# lilium_network register map
Vendor: Nordic Semiconductor; Series: nrfXX; File version: 1
CPU: CM33 r0p4, little endian, MPU, no FPU, 3 interrupt priority bits, 30 interrupts
Registers are 32-bit, read-write, reset 0x0 unless marked. A register's access mark holds for its fields unless they carry their own. Offsets are from the block's base; [hi:lo] are bit positions; lines under a group give offsets from that group; {n}, {i} and the like mark numbered series; 'fields as' and 'values as' point back to an identical list.

## RADIO (part 3 of 3) — 2.4 GHz radio
Base 0x41008000
0x914 DECFILTERS group — Unspecified
  0x00 OUTMAIN group — Unspecified
    0x00 CKSEL reset 0x2 — Clock select register for the output outMain
      [2:0] CKSEL — Number of times to divide the base clock rate by 2. Exception: highest value gives BYPASS, ie. clock is disabled and data out is assigned directly from data in.
        0=ClkSel32M (CKSEL_32M); 1=ClkSel16M (CKSEL_16M); 2=ClkSel8M (CKSEL_8M); 3=ClkSel4M (CKSEL_4M); 4=ClkSel2M (CKSEL_2M); 5=ClkSel1M (CKSEL_1M); 6=ClkSel500K (CKSEL_500K); 7=ClkSelBypass (CKSEL_BYPASS)
  0x04 DECFIR0 group — Unspecified
    0x00 CKSEL reset 0x7 — Clock select register for the PUnit decFIR0 of type IP_FIR
      fields as DECFILTERS.OUTMAIN.CKSEL
    0x04 CONTROL reset 0x2 — Control register for the PUnit decFIR0 of type IP_FIR
      [1:0] TAPSEL — Tap-select: number of active taps minus 2
    0x08 COEFFS0 reset 0x4 — Coefficient register 0 for the PUnit decFIR0 of type IP_FIR
      [3:0] COEFF0 — Signed filter coefficient 0
    0x0C COEFFS1 reset 0x6 — Coefficient register 1 for the PUnit decFIR0 of type IP_FIR
      [3:0] COEFF1 — Signed filter coefficient 1
    0x10 COEFFS2 reset 0x6 — Coefficient register 2 for the PUnit decFIR0 of type IP_FIR
      [3:0] COEFF2 — Signed filter coefficient 2
    0x14 COEFFS3 — Coefficient register 3 for the PUnit decFIR0 of type IP_FIR
      [3:0] COEFF3 — Signed filter coefficient 3
  0x1C DECFIR1 group — Unspecified
    0x00 CKSEL — Clock select register for the PUnit decFIR1 of type IP_FIR
      fields as DECFILTERS.OUTMAIN.CKSEL
    0x04 CONTROL reset 0x4 — Control register for the PUnit decFIR1 of type IP_FIR
      [2:0] TAPSEL — Tap-select: number of active taps minus 2
    0x08 COEFFS0 reset 0x8 — Coefficient register 0 for the PUnit decFIR1 of type IP_FIR
      [5:0] COEFF0 — Signed filter coefficient 0
    0x0C COEFFS1 reset 0x10 — Coefficient register 1 for the PUnit decFIR1 of type IP_FIR
      [5:0] COEFF1 — Signed filter coefficient 1
    0x10 COEFFS2 reset 0x18 — Coefficient register 2 for the PUnit decFIR1 of type IP_FIR
      [5:0] COEFF2 — Signed filter coefficient 2
    0x14 COEFFS3 reset 0x10 — Coefficient register 3 for the PUnit decFIR1 of type IP_FIR
      [5:0] COEFF3 — Signed filter coefficient 3
    0x18 COEFFS4 — Coefficient register 4 for the PUnit decFIR1 of type IP_FIR
      [5:0] COEFF4 — Signed filter coefficient 4
    0x1C COEFFS5 — Coefficient register 5 for the PUnit decFIR1 of type IP_FIR
      [5:0] COEFF5 — Signed filter coefficient 5
  0x3C DECFIR2 group — Unspecified
    0x00 CKSEL reset 0x1 — Clock select register for the PUnit decFIR2 of type IP_FIR
      fields as DECFILTERS.OUTMAIN.CKSEL
    0x04 CONTROL reset 0x4 — Control register for the PUnit decFIR2 of type IP_FIR
      [2:0] TAPSEL — Tap-select: number of active taps minus 2
    0x08 COEFFS0 reset 0x8 — Coefficient register 0 for the PUnit decFIR2 of type IP_FIR
      [5:0] COEFF0 — Signed filter coefficient 0
    0x0C COEFFS1 reset 0x10 — Coefficient register 1 for the PUnit decFIR2 of type IP_FIR
      [5:0] COEFF1 — Signed filter coefficient 1
    0x10 COEFFS2 reset 0x18 — Coefficient register 2 for the PUnit decFIR2 of type IP_FIR
      [5:0] COEFF2 — Signed filter coefficient 2
    0x14 COEFFS3 reset 0x10 — Coefficient register 3 for the PUnit decFIR2 of type IP_FIR
      [5:0] COEFF3 — Signed filter coefficient 3
    0x18 COEFFS4 — Coefficient register 4 for the PUnit decFIR2 of type IP_FIR
      [5:0] COEFF4 — Signed filter coefficient 4
    0x1C COEFFS5 — Coefficient register 5 for the PUnit decFIR2 of type IP_FIR
      [5:0] COEFF5 — Signed filter coefficient 5
0x970 CHANNELFILTERS group — Unspecified
  0x00 OUTMAIN group — Unspecified
    0x00 CKSEL reset 0x2 — Clock select register for the output outMain
      fields as DECFILTERS.OUTMAIN.CKSEL
    0x04 SOURCE reset 0x4 — Source select register for the output outMain
      [3:0] SOURCE — Data source select
        15=SRC_INMAIN (NOT LEGAL); 0=SRC_IIR0 (NOT LEGAL); 1=SRC_IIR1 (NOT LEGAL); 2=SRC_NOTCHIIR0 (NOT LEGAL); 3=SrcNotchIIR1; 4=SrcDecFIR
  0x08 OUTPEAKDET group — Unspecified
    0x00 CKSEL reset 0x2 — Clock select register for the output outPeakDet
      fields as DECFILTERS.OUTMAIN.CKSEL
    0x04 SOURCE reset 0x3 — Source select register for the output outPeakDet
      fields as CHANNELFILTERS.OUTMAIN.SOURCE
  0x10 IIR0 group — Unspecified
    0x00 CKSEL reset 0x2 — Clock select register for the PUnit IIR0 of type IP_IIR2
      fields as DECFILTERS.OUTMAIN.CKSEL
    0x04 STATUS write-1-clears — Status register for the PUnit IIR0 of type IP_IIR2
      [1:0] IQSATURATION — Saturation status for I/Q (bit 0/1) component (bitwise write 1 to clear)
    0x08 COEFFSB0 reset 0x80 — Coefficient register B0 for the PUnit IIR0 of type IP_IIR2
      [11:0] COEFFB0 — Signed filter coefficient B0
    0x0C COEFFSB1 reset 0x80 — Coefficient register B1 for the PUnit IIR0 of type IP_IIR2
      [11:0] COEFFB1 — Signed filter coefficient B1
    0x10 COEFFSB2 — Coefficient register B2 for the PUnit IIR0 of type IP_IIR2
      [11:0] COEFFB2 — Signed filter coefficient B2
    0x14 COEFFSA1 reset 0xD00 — Coefficient register A1 for the PUnit IIR0 of type IP_IIR2
      [11:0] COEFFA1 — Signed filter coefficient A1
    0x18 COEFFSA2 — Coefficient register A2 for the PUnit IIR0 of type IP_IIR2
      [11:0] COEFFA2 — Signed filter coefficient A2
  0x2C IIR1 group — Unspecified
    0x00 CKSEL reset 0x2 — Clock select register for the PUnit IIR1 of type IP_IIR2
      fields as DECFILTERS.OUTMAIN.CKSEL
    0x04 STATUS write-1-clears — Status register for the PUnit IIR1 of type IP_IIR2
      fields as CHANNELFILTERS.IIR0.STATUS
    {0x8+4k} COEFFSB{k} reset 0x60 (k=0..2) — Coefficient register B{k} for the PUnit IIR1 of type IP_IIR2
      [11:0] COEFFB{k} — Signed filter coefficient B{k}
    0x14 COEFFSA1 reset 0xA00 — Coefficient register A1 for the PUnit IIR1 of type IP_IIR2
      [11:0] COEFFA1 — Signed filter coefficient A1
    0x18 COEFFSA2 reset 0x300 — Coefficient register A2 for the PUnit IIR1 of type IP_IIR2
      [11:0] COEFFA2 — Signed filter coefficient A2
  0x48 NOTCHIIR0 group — Unspecified
    0x00 CKSEL reset 0x2 — Clock select register for the PUnit notchIIR0 of type IP_IIR2
      fields as DECFILTERS.OUTMAIN.CKSEL
    0x04 SOURCE reset 0x1 — Source select register for the PUnit notchIIR0 of type IP_IIR2
      [3:0] SOURCE — Data source select
        15=SRC_INMAIN (NOT LEGAL); 0=SRC_IIR0 (NOT LEGAL); 1=SrcIIR1; 2=SRC_NOTCHIIR0 (NOT LEGAL); 3=SRC_NOTCHIIR1 (NOT LEGAL); 4=SrcDecFIR
    0x08 STATUS write-1-clears — Status register for the PUnit notchIIR0 of type IP_IIR2
      fields as CHANNELFILTERS.IIR0.STATUS
    0x0C COEFFSB0 reset 0x3C0 — Coefficient register B0 for the PUnit notchIIR0 of type IP_IIR2
      [11:0] COEFFB0 — Signed filter coefficient B0
    0x10 COEFFSB1 reset 0xAB0 — Coefficient register B1 for the PUnit notchIIR0 of type IP_IIR2
      [11:0] COEFFB1 — Signed filter coefficient B1
    0x14 COEFFSB2 reset 0x3C0 — Coefficient register B2 for the PUnit notchIIR0 of type IP_IIR2
      [11:0] COEFFB2 — Signed filter coefficient B2
    0x18 COEFFSA1 reset 0xAB0 — Coefficient register A1 for the PUnit notchIIR0 of type IP_IIR2
      [11:0] COEFFA1 — Signed filter coefficient A1
    0x1C COEFFSA2 reset 0x380 — Coefficient register A2 for the PUnit notchIIR0 of type IP_IIR2
      [11:0] COEFFA2 — Signed filter coefficient A2
  0x68 NOTCHIIR1 group — Unspecified
    0x00 CKSEL reset 0x7 — Clock select register for the PUnit notchIIR1 of type IP_IIR2
      fields as DECFILTERS.OUTMAIN.CKSEL
    0x04 STATUS write-1-clears — Status register for the PUnit notchIIR1 of type IP_IIR2
      fields as CHANNELFILTERS.IIR0.STATUS
    {0x8+4k} COEFFSB{k} (k=0..2) — Coefficient register B{k} for the PUnit notchIIR1 of type IP_IIR2
      [11:0] COEFFB{k} — Signed filter coefficient B{k}
    0x14 COEFFSA1 — Coefficient register A1 for the PUnit notchIIR1 of type IP_IIR2
      [11:0] COEFFA1 — Signed filter coefficient A1
    0x18 COEFFSA2 — Coefficient register A2 for the PUnit notchIIR1 of type IP_IIR2
      [11:0] COEFFA2 — Signed filter coefficient A2
  0x84 DECFIR group — Unspecified
    0x00 CKSEL reset 0x7 — Clock select register for the PUnit decFIR of type IP_FIR
      fields as DECFILTERS.OUTMAIN.CKSEL
    0x04 SOURCE reset 0x3 — Source select register for the PUnit decFIR of type IP_FIR
      [3:0] SOURCE — Data source select
        15=SRC_INMAIN (NOT LEGAL); 0=SRC_IIR0 (NOT LEGAL); 1=SrcIIR1; 2=SRC_NOTCHIIR0 (NOT LEGAL); 3=SrcNotchIIR1; 4=SRC_DECFIR (NOT LEGAL)
    0x08 CONTROL reset 0x4 — Control register for the PUnit decFIR of type IP_FIR
      [2:0] TAPSEL — Tap-select: number of active taps minus 2
    0x0C COEFFS0 reset 0x8 — Coefficient register 0 for the PUnit decFIR of type IP_FIR
      [5:0] COEFF0 — Signed filter coefficient 0
    0x10 COEFFS1 reset 0x10 — Coefficient register 1 for the PUnit decFIR of type IP_FIR
      [5:0] COEFF1 — Signed filter coefficient 1
    0x14 COEFFS2 reset 0x18 — Coefficient register 2 for the PUnit decFIR of type IP_FIR
      [5:0] COEFF2 — Signed filter coefficient 2
    0x18 COEFFS3 reset 0x10 — Coefficient register 3 for the PUnit decFIR of type IP_FIR
      [5:0] COEFF3 — Signed filter coefficient 3
    0x1C COEFFS4 — Coefficient register 4 for the PUnit decFIR of type IP_FIR
      [5:0] COEFF4 — Signed filter coefficient 4
    0x20 COEFFS5 — Coefficient register 5 for the PUnit decFIR of type IP_FIR
      [5:0] COEFF5 — Signed filter coefficient 5
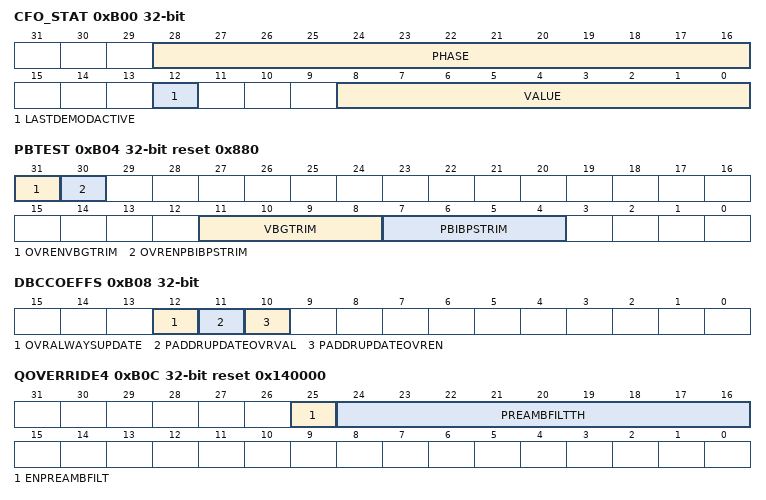
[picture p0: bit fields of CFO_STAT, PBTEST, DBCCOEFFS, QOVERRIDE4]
0xB00 CFO_STAT ro — Carrier freq. offset estimate
  [28:16] PHASE — Readout of last valid phase set in correlator (hypermode only) (signed)
  [12] LASTDEMODACTIVE — 0: Standard mode was used last 1: Hypermode was last used
  [8:0] VALUE — Readout of last valid decision level set in BitSlicer (signed)
0xB04 PBTEST reset 0x880 — Test: PB calibration
  [31] OVRENVBGTRIM — if '1' enable override for VBGTRIM
  [30] OVRENPBIBPSTRIM — if '1' enable override for PBIBPSTRIM
  [11:8] VBGTRIM — Trim code for VBG to FS_VCOREG
  [7:4] PBIBPSTRIM — Trim code for IBPS currents
0xB08 DBCCOEFFS — Test and Debug: DBC coefficients override
  [12] OVRALWAYSUPDATE — Zero means coefficients only updated when needed (default), set to 1 coefficients are always updated when the radio is enabled.
  [11] PADDRUPDATEOVRVAL
  [10] PADDRUPDATEOVREN
0xB0C QOVERRIDE4 reset 0x140000 — Trim value override register 4 for nRF52
  [25] ENPREAMBFILT — Enable preamble filter
  [24:16] PREAMBFILTTH — Threshold for the preamble filter
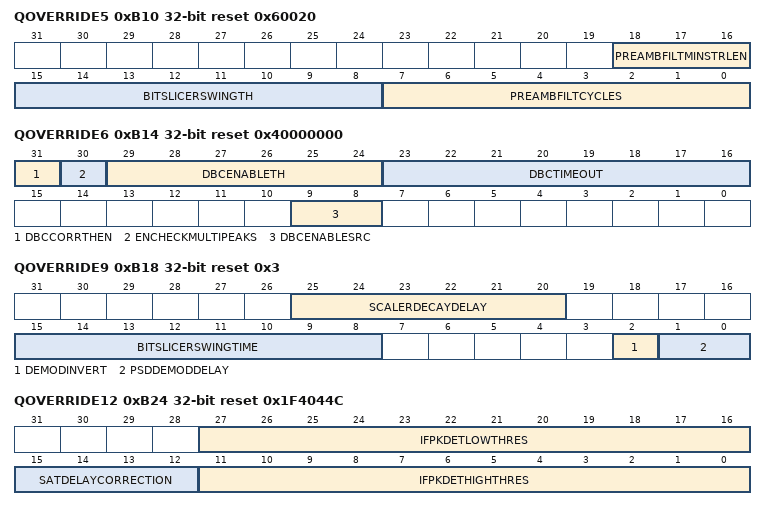
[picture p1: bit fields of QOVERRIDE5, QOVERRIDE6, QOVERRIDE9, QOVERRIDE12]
0xB10 QOVERRIDE5 reset 0x60020 — Trim value override register 5 for nRF52
  [18:16] PREAMBFILTMINSTRLEN — Override value for preambFiltMinStrLen
  [15:8] BITSLICERSWINGTH — Override value for bitSlicerSwingTh
  [7:0] PREAMBFILTCYCLES — Override value for preambFiltCycles
0xB14 QOVERRIDE6 reset 0x40000000 — Trim value override register 6 for nRF52
  [31] DBCCORRTHEN — Override value enable for DBCCORRTH and MFBSTRBOFFSET
  [30] ENCHECKMULTIPEAKS — Enable checking of several correlator peaks in hypermode
  [29:24] DBCENABLETH — Override value for correlator enable threshold
  [23:16] DBCTIMEOUT — Override value for correlator timeout,in bit periods (hypermode)
  [9:8] DBCENABLESRC — Override value for dbcEnableSrc
    0=Always on when not address match; 1=BBLogMag (When bbLogMag is above a threshold); 2=BitSlicerSwing (When a certain time has gone since the input to the bitslicer was above BITSLICERSWINGTH); 3=Both BBLogMag and BitSlicerSwing
0xB18 QOVERRIDE9 reset 0x3 — Trim value override register 9 for nRF52
  [25:20] SCALERDECAYDELAY — Decay delay for the IQ scaler
  [15:8] BITSLICERSWINGTIME
  [2] DEMODINVERT — Override value for demodInvert (standard and hyper)
  [1:0] PSDDEMODDELAY — Override value for psdDemodDelay (standard mode)
0xB24 QOVERRIDE12 reset 0x1F4044C — Trim value override register 12 for nRF52
  [27:16] IFPKDETLOWTHRES — Override value for IfpkDetLowThres
  [15:12] SATDELAYCORRECTION — Signed correction value for how much the saturation information is delayed from the input ADC samples to the samples being stored to RAM in direction finding operation
  [11:0] IFPKDETHIGHTHRES — Override value for IfpkDetHighThres
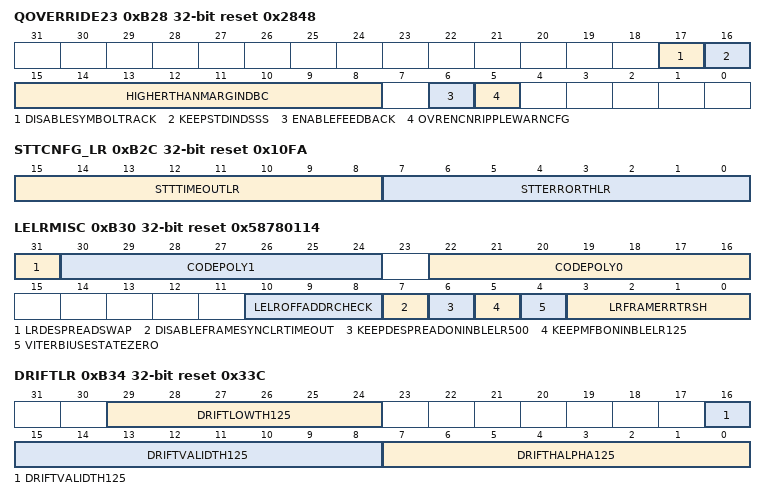
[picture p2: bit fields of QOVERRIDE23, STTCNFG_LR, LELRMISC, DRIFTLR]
0xB28 QOVERRIDE23 reset 0x2848 — Trim value override register 23 for nRF52
  [17] DISABLESYMBOLTRACK — Disable symbol tracking for IEEE 802.15.4 and BLE LR modes
  [16] KEEPSTDINDSSS — Keep standard demod in DSSS mode
  [15:8] HIGHERTHANMARGINDBC — Required peak height required for a double correlator peak to be considered higher than previous ones. The register value will be multiplied by 25 to obtain the actual margin. The bitfield is NOT subject to the enable override at bit position 31, and will always be enabled for hypermode.
  [6] ENABLEFEEDBACK — Enable decision feedback for matched filter bank
  [5] OVRENCNRIPPLEWARNCFG — Override enable for CNPEAKMINTHR and CNABSMAXTHR in the CNRIPPLEWARNCFG register
0xB2C STTCNFG_LR reset 0x10FA — Strobe time tracking configuration in long range mode
  [15:8] STTTIMEOUTLR — Strobe time tracking timeout in BLE LR mode
  [7:0] STTERRORTHLR — Strobe time tracking error threshold in BLE LR mode
0xB30 LELRMISC reset 0x58780114 — Miscellaneous Controls for Long Range
  [31] LRDESPREADSWAP — Swap de-spreader
  [30:24] CODEPOLY1 — Code Polynom 1
  [22:16] CODEPOLY0 — Code Polynom 0
  [10:8] LELROFFADDRCHECK — The number of chip periods earlier which it is allowed to declare frameSync in DecodeLELong
  [7] DISABLEFRAMESYNCLRTIMEOUT — Disable framesync timeout (early address match timeout) for BLE LR mode (hypermode).
  [6] KEEPDESPREADONINBLELR500 — Do not stop the clock to the Despreader in BLE LR 500 mode
  [5] KEEPMFBONINBLELR125 — Do not stop the clock to RxMFB in BLE LR 125 mode
  [4] VITERBIUSESTATEZERO — Use Viterbi state zero when flushing out bits for BLE LR
  [3:0] LRFRAMERRTRSH — Framer Receive Threshold
0xB34 DRIFTLR reset 0x33C — Drift Controls in Long Range
  [29:24] DRIFTLOWTH125 — Override value for driftLowTh, drift estimator (despreadLELLong)
  [16:8] DRIFTVALIDTH125 — Override value for driftValidTh, drift estimator (despreadLELLong)
  [7:0] DRIFTHALPHA125 — Override value for IIR feedback , drift estimator (despreadLELLong)
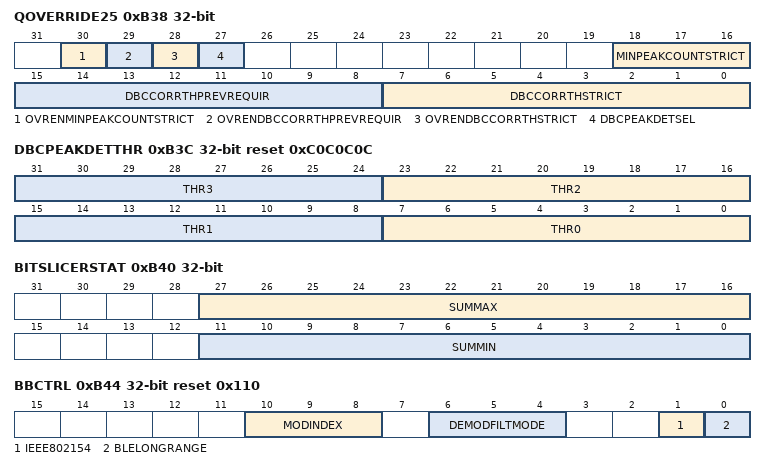
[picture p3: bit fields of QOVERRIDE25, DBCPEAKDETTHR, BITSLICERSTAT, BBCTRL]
0xB38 QOVERRIDE25 — TODO
  [30] OVRENMINPEAKCOUNTSTRICT — Override enable for MINPEAKCOUNTSTRICT
  [29] OVRENDBCCORRTHPREVREQUIR — Override enable for DBCCORRTHPREVREQUIR
  [28] OVRENDBCCORRTHSTRICT — Override enable for DBCCORRTHSTRICT
  [27] DBCPEAKDETSEL — DBC peak detector selection
    0=Classic (Use classic peak detector (backward compatible behavior)); 1=Differential (Use differential peak detector)
  [18:16] MINPEAKCOUNTSTRICT — Min number of peaks to detect before resyncing to another preamble while already working on a previous preamble in BleLrx.
  [15:8] DBCCORRTHPREVREQUIR — Correlation threshold for double correlator used in BleLr mode to reject a later resync using DBCCORRTHSTRICT.
  [7:0] DBCCORRTHSTRICT — Correlation threshold for double correlator used in BleLr mode to resync to another preamble while already working on a previous preamble.
0xB3C DBCPEAKDETTHR reset 0xC0C0C0C — Thresholds for each peak detector instance
  [8n+7:8n] THR{n} (n=0..3) — Diff threshold {n}
0xB40 BITSLICERSTAT ro — Payload status
  [27:16] SUMMAX — Number of received ones
  [11:0] SUMMIN — Number of received zeros
0xB44 BBCTRL reset 0x110 — Miscellaneous mode bits
  [10:8] MODINDEX — Modulation index for RxDBCCoeffGen and RxMFB
    0=0h25 (Modulation index h=0.25); 1=0h32 (Modulation index h=0.32); 2=0h5 (Modulation index h=0.5); 3=1h0 (Modulation index h=1.0); 4=2h0 (Modulation index h=2.0)
  [6:4] DEMODFILTMODE — Decimation mode in PantherDemodFilt
    0=2M (Decimation mode 2M); 1=1M (Decimation mode 1M); 3=250K (Decimation mode 250K)
  [1] IEEE802154 — Enable 15.4 mode (enabling both 15.4 and long range is not legal)
    0=Disable (IEEE802154_NO); 1=Enable (IEEE802154_YES)
  [0] BLELONGRANGE — Enable long range mode (enabling both 15.4 and long range is not legal)
    0=Disable (BLELONGRANGE_NO); 1=Enable (BLELONGRANGE_YES)
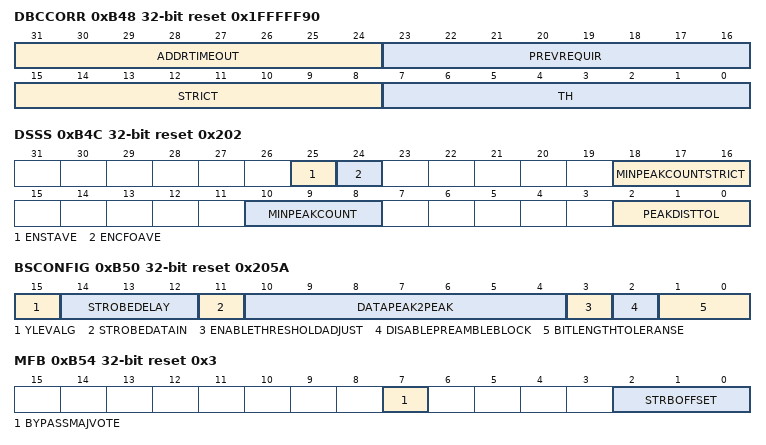
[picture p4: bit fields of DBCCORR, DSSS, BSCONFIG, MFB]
0xB48 DBCCORR reset 0x1FFFFF90 — Thresholds for the double correlator
  [31:24] ADDRTIMEOUT — Override value for address match timeout, [in bit periods] (hypermode). 0 means no timeout. If BALEN is 3, the actual value of DBCADDRTIMEOUT will be the value written to this register minus 8.
  [23:16] PREVREQUIR — Correlation threshold for double correlator used in BleLr mode to reject a later resync using DBCCORRTHSTRICT. Also applies for Ieee 802.15.4 mode
  [15:8] STRICT — Correlation threshold for double correlator used in BleLr mode to resync to another preamble while already working on a previous preamble. Also applies for Ieee 802.15.4 mode
  [7:0] TH — Correlation threshold for double correlator in normal operation
0xB4C DSSS reset 0x202 — DSSS synchronizer trim values
  [25] ENSTAVE — Enable strobe time averaging
  [24] ENCFOAVE — Enable CFO averaging
  [18:16] MINPEAKCOUNTSTRICT — Min number of peaks to detect before resyncing to another preamble while already working on a previous preamble in BleLrx. Also applies for Ieee 802.15.4 mode
  [10:8] MINPEAKCOUNT — Override for dsssMinPeakCount
  [2:0] PEAKDISTTOL — Override for dsssPeakDistanceTolerance
0xB50 BSCONFIG reset 0x205A — Bitslicer configuration
  [15] YLEVALG — Override for bsYlevAlg
  [14:12] STROBEDELAY — Override for bsStrobeDelay
  [11] STROBEDATAIN — Override for bsStrobeDataIn
  [10:4] DATAPEAK2PEAK — Override for bsDataPeak2Peak
  [3] ENABLETHRESHOLDADJUST — Override for bsEnableThresholdAdjust
  [2] DISABLEPREAMBLEBLOCK — Override for bsDisablePreambleBlock
  [1:0] BITLENGTHTOLERANSE — Override for bsBitLengthToleranse
0xB54 MFB reset 0x3 — Matched Filter Bank (MFB) configuration
  [7] BYPASSMAJVOTE — Bypass majority vote
    0=PASS (Majority vite); 1=BYPASS (Bypass through majority vote)
  [2:0] STRBOFFSET — Override value for strobe offset
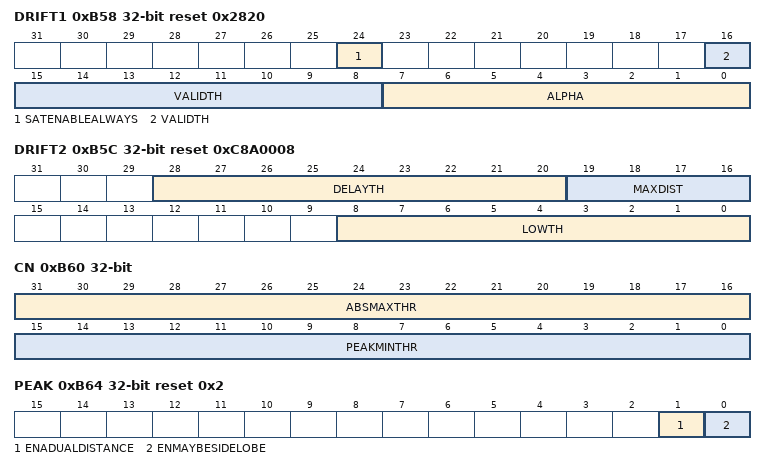
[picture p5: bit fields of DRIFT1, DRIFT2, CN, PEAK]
0xB58 DRIFT1 reset 0x2820 — Drift Estimator configuration
  [24] SATENABLEALWAYS — Enable saturation in drift calculator for all modes
  [16:8] VALIDTH — Override value for driftValidTh, drift estimator (hypermode)
  [7:0] ALPHA — Override value for IIR feedback , drift estimator (hypermode)
0xB5C DRIFT2 reset 0xC8A0008 — Drift Estimator configuration
  [28:20] DELAYTH — Override value for driftDelayTh, drift estimator (hypermode)
  [19:16] MAXDIST — Override value for driftMaxDist, drift estimator (hypermode)
  [8:0] LOWTH — Override value for driftLowTh, drift estimator (hypermode)
0xB60 CN — Configuration for the CNRIPPLEWARN functionality used for BLE LR. Configuration is only enabled when OVRENCNRIPPLEWARNCFG in OVERRIDE23 is set
  [31:16] ABSMAXTHR — maximum baseline value before the peak at the double correlator output. if the baseline value is above the threshold, the following peak will be ignored. this value is ignored when CNABSMAXTHR is set to 0x0000.
  [15:0] PEAKMINTHR — Required peak height compared to baseline level measured just before the peak at the double correlator output. If the peak height is below the threshold, it will be ignored. This feature is disabled when CNPEAKMINTHR is set to 0x0000.
0xB64 PEAK reset 0x2 — Peak detector configuration
  [1] ENADUALDISTANCE — Allow dual distance between peaks
  [0] ENMAYBESIDELOBE — Ignore peaks from DBC which look like sidelobes
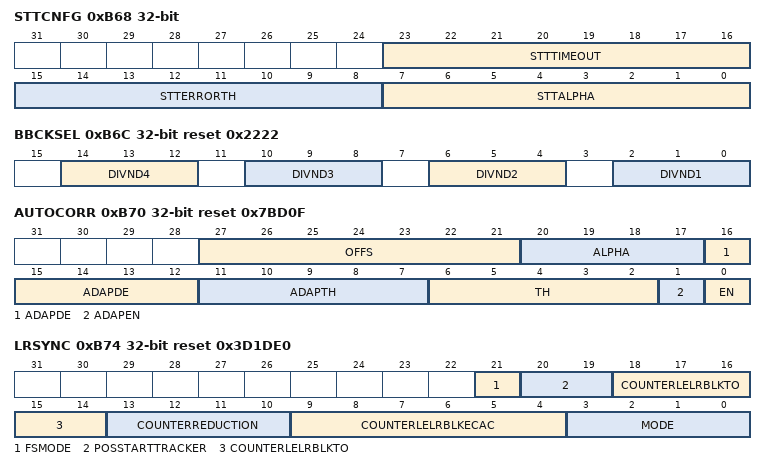
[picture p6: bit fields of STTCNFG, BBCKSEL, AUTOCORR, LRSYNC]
0xB68 STTCNFG — Strobe time tracking Configuration (Symbol Timing)
  [23:16] STTTIMEOUT — Strobe time tracking: adjustment timeout (min distance in symbolperiods between strobe adjustments in same direction)
  [15:8] STTERRORTH — Strobe time tracking: strobe time error threshold
  [7:0] STTALPHA — Strobe time tracking: IIR filter alpha
0xB6C BBCKSEL reset 0x2222 — Clock rates
  [all] fields
    0=32M (Select clock rate 32M); 1=16M (Select clock rate 16M); 2=8M (Select clock rate 8M); 3=4M (Select clock rate 4M); 4=2M (Select clock rate 2M); 5=1M (Select clock rate 1M); 6=500K (Select clock rate 500K); 7=Disabled (Select clock OFF)
  [14:12] DIVND4 — Hyper demod clock rate 2
  [10:8] DIVND3 — Hyper demod clock rate 1
  [6:4] DIVND2 — Standard demod clock rate 2
  [2:0] DIVND1 — Standard demod clock rate 1
0xB70 AUTOCORR reset 0x7BD0F — Autocorrelator configuration
  [27:21] OFFS — Offset for comparing between current and historical AC magnitude
  [20:17] ALPHA — Gain factor for low pass filter used to smoothen autocorrelator output. Set to 0000 indicates to select Max filter instead of LPF.
  [16:12] ADAPDE — A ratio to decay the autocorrelator ratio threshold when using adaptive threshold and a weak peak is found.
  [11:7] ADAPTH — A ratio to update the autocorrelator ratio threshold when adaptive threshold is enabled and a strong peak is found. Fraction of highest correlator match historically seen. Setting of 0.8125 is default.
  [6:2] TH — Default correlator threshold for deciding if valid correlator match is seen. Low setting of 0.10 is default.
  [1] ADAPEN — Enable adaptive autocorrelator threshold settings based on historically observed correlator output values.
  [0] EN — Enable autocorrelator gating of peaks.
0xB74 LRSYNC reset 0x3D1DE0 — LrSyncEngine configuration
  [21] FSMODE — Select between classic and MLSD based frame sync
    0=classic mode; 1=MLSD mode
  [20:19] POSSTARTTRACKER — A toggle to tell when to start the trackers inside each LelrBlk125.
    0=disabled for all times; 1=enabled after FEC1 is decoded; 2=enabled after frame sync is achieved; 3=enabled after LelrBlk125 is activated
  [18:14] COUNTERLELRBLKTO — A counter is used to reset the LelrBlk125 block that is active. It counts the number of outputs from DeSpreadLELong and compares it with this configured value to see whether a timeout event happens. The range is 32 to 60. Default value is 52.
  [13:10] COUNTERREDUCTION — When a strong peak event is triggered and the average peak strength is higher than the history stored in the block, the timeout counter is reduced by the number configured in this register. The default value is 7.
  [9:4] COUNTERLELRBLKECAC — A counter is used to indicate the time window of e-CAC check. It counts the number of outputs from DeSpreadLELong and compares it with this configured value to see whether e-CAC result is valid.
  [3:0] MODE — Modifying how the multiple lr125Front modules are used when synchronizing.
    0=AllFrontends (Use all the front ends); 1=OneFrontend (Use only one front end)
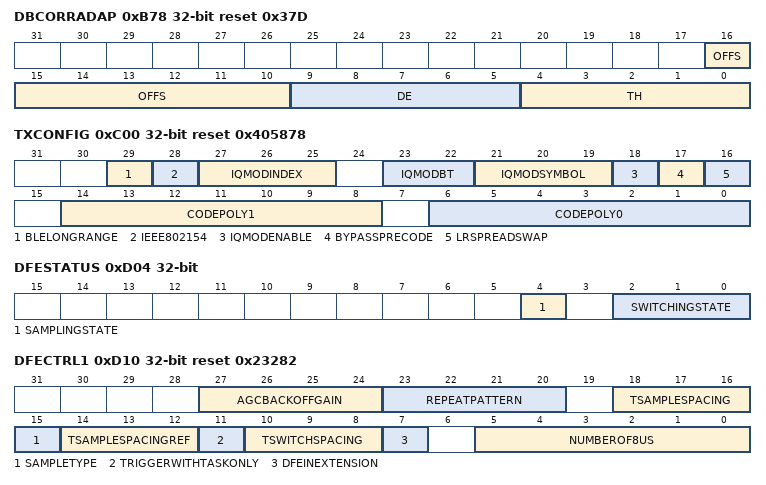
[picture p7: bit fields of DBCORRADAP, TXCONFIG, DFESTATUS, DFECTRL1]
0xB78 DBCORRADAP reset 0x37D — Adaptive thresholds for double correlator.
  [16:10] OFFS — Offset for comparing between current and historical DBC magnitude
  [9:5] DE — A ratio to decay the DBC ration threshold when using adaptive threshold and a weak peak is found.
  [4:0] TH — A ratio to update the DBC ratio threshold when adaptive threshold is enabled and a strong peak is found. Fraction of highest correlator match historically seen. Setting of 0.90625 is default.
0xB7C QOVERRIDE26 reset 0x1 — Override for selecting whether to use LrSyncEngine or the classic demodulator.
  [0] USELRSYNCENGINE — Select whether to use LrSyncEngine or the classic demodulator.
    0=Classic (use classic demodulator); 1=LrSyncEngine (Use LrSyncEngine demodulator)
0xC00 TXCONFIG reset 0x405878 — Tx configuration
  [29] BLELONGRANGE — Enable Tx for BLE long range modes (Do not enable both Ieee802154_250Kbit and BLE long range)
    0=Disabled (Disable Tx for BLE long range modes); 1=Enabled (Enable Tx for BLE long range modes)
  [28] IEEE802154 — Enable Tx for Ieee802154_250Kbit mode and long range modes (Do not enable both Ieee802154_250Kbit and long range)
    0=Disabled (Disable Tx for Ieee802154_250Kbit mode); 1=Enabled (Enable Tx for Ieee802154_250Kbit mode)
  [27:25] IQMODINDEX — IQMOD modulation index
    0=ModIndex0h25 (Modulation index = 0.25(Future)); 1=ModIndex0h32 (Modulation index = 0.32(Future)); 2=ModIndex0h5 (Modulation index = 0.5(Future)); 3=ModIndex1h0 (Modulation index = 1(Future)); 4=ModIndex2h0 (Modulation index = 2(Future))
  [23:22] IQMODBT — IQMOD GFSK bandwidth
    0=0BT55 (BT=0.55); 1=0BT60 (BT=0.60)
  [21:19] IQMODSYMBOL — IQMOD additional symbol mapping not set by MODE(Future)
  [18] IQMODENABLE — Enable IQ modulator
  [17] BYPASSPRECODE — Bypass MSK precoding
  [16] LRSPREADSWAP — Swap pattern mapping. Default 0, 0 is mapped to a 0011 sequence, 1 is mapped to a 1100 sequence. If swap bit is set, 1 is mapped to a 0011 sequence, 0 is mapped to a 1100 sequence.
  [14:8] CODEPOLY1 — Code polynomial 1
  [6:0] CODEPOLY0 — Code polynomial 0
0xD00 DFEMODE — Whether to use Angle-of-Arrival (AOA) or Angle-of-Departure (AOD)
  [1:0] DFEOPMODE — Direction finding operation mode
    0=Disabled (Direction finding mode disabled); 2=AoD (Direction finding mode set to AoD); 3=AoA (Direction finding mode set to AoA)
0xD04 DFESTATUS ro — DFE status information
  [4] SAMPLINGSTATE — Internal state of sampling state machine
    0=Idle (Sampling state Idle); 1=Sampling state Sampling
  [2:0] SWITCHINGSTATE — Internal state of switching state machine
    0=Idle (Switching state Idle); 1=Offset (Switching state Offset); 2=Guard (Switching state Guard); 3=Ref (Switching state Ref); 4=Switching state Switching; 5=Ending (Switching state Ending)
0xD10 DFECTRL1 reset 0x23282 — Various configuration for Direction finding
  [27:24] AGCBACKOFFGAIN — Gain will be lowered by the specified number of gain steps at the start of CTE
  [23:20] REPEATPATTERN — Repeat every antenna pattern N times.
    0=NoRepeat (Do not repeat (1 time in total))
  [18:16] TSAMPLESPACING — Interval between samples in the SWITCHING period when CTEINLINECTRLEN is 0
    1=4us; 2=2us; 3=1us; 4=500ns (0.5us); 5=250ns (0.25us); 6=125ns (0.125us)
  [15] SAMPLETYPE — Whether to sample I/Q or magnitude/phase
    0=IQ (Complex samples in I and Q); 1=MagPhase (Complex samples as magnitude and phase)
  [14:12] TSAMPLESPACINGREF — Interval between samples in the REFERENCE period
    0=8us; 1=4us; 2=2us; 3=1us; 4=500ns (0.5us); 5=250ns (0.25us); 6=125ns (0.125us)
  [11] TRIGGERWITHTASKONLY — Trigger AoA/AoD procedure using only task
    1=OnlyTask (Only allow triggering a procedure with TASKS_DFESTART); 0=Multiple (Trigger also with other signals)
  [10:8] TSWITCHSPACING — Interval between every time the antenna is changed in the SWITCHING state
    0=8us; 1=4us; 2=2us; 3=1us; 4=500ns (0.5us); 5=250ns (0.25us)
  [7] DFEINEXTENSION — Add CTE extension and do antenna switching/sampling in this extension
    1=CRC (AoA/AoD procedure triggered at end of CRC); 0=Payload (Antenna switching/sampling is done in the packet payload)
  [5:0] NUMBEROF8US — Length of the AoA/AoD procedure in number of 8 us units
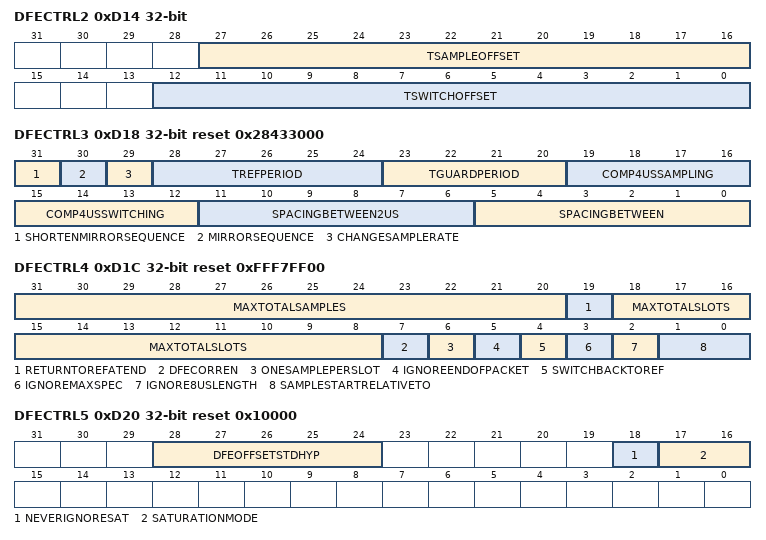
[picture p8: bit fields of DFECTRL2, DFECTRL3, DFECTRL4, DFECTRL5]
0xD14 DFECTRL2 — Start offset for Direction finding
  [27:16] TSAMPLEOFFSET — Signed value offset before starting sampling in number of 16M cycles relative to the beginning of the REFERENCE state - 12 us after switching start
  [12:0] TSWITCHOFFSET — Signed value offset after the end of the CRC before starting switching in number of 16M cycles
0xD18 DFECTRL3 reset 0x28433000 — Various hacker/tuning configuration for Direction finding
  [31] SHORTENMIRRORSEQUENCE — Applies only when MIRRORSEQUENCE is set. Selects whether to repeat the end pattern (in both ends) or not
    0=Disable (End patterns are repeated); 1=Enable (End patterns are not repeated)
  [30] MIRRORSEQUENCE — When reaching the last antenna pattern, it repeats that pattern, and then goes back down again.
    0=Disable (Do not mirror the sequence); 1=Enable (Mirror the sequence)
  [29] CHANGESAMPLERATE — Whether to have the ability to have separate sampling rate in the REFERENCE period vs the SWITCHING state
    0=Same (Always use sample spacing given by TSAMPLESPACINGREF); 1=Change (Use TSAMPLESPACINGREF in the REFERENCE period, and TSAMPLESPACING or CTEINLINEAODRXMODExUS in the SWITCHING period)
  [28:24] TREFPERIOD — Length of REFERENCE period in number of microseconds, normally 8
  [23:20] TGUARDPERIOD — Length of GUARD period in number of microseconds, normally 4
  [19:16] COMP4USSAMPLING — Number of 4us periods to subtract from numberOf8us when calculating total number of samples to capture
  [15:12] COMP4USSWITCHING — Number of 4us periods to subtract from numberOf8us when calculating total number of antenna slots switches
  [11:6] SPACINGBETWEEN2US — Same as SPACINGBETWEEN when using CTEINLINECTRL and CTEType is 2 us slots
  [5:0] SPACINGBETWEEN — Signed tuning value for the spacing between the last sample in the reference period and the first sample in the first sample slot
0xD1C DFECTRL4 reset 0xFFF7FF00 — Various hacker/tuning configuration for Direction finding
  [31:20] MAXTOTALSAMPLES — Maximum number of samples to capture
  [19] RETURNTOREFATEND — Start position of repeated part of switching pattern sequence
    0=Disable (Return to SWITCHPATTERN[2] after reaching the end of the switching pattern sequence); 1=Enable (Return to SWITCHPATTERN[1] after reaching the end of the switching pattern sequence)
  [18:8] MAXTOTALSLOTS — Maximum number of antenna slots
  [7] DFECORREN — Enable correlator before Direction Finding samples
    0=Disable correlator; 1=Enable correlator
  [6] ONESAMPLEPERSLOT — TSAMPLESPACING is ignored for the samples taken in the SWITCHING state TSAMPLESPACINGREF is still used for the first samples (REFERENCE period)
  [5] IGNOREENDOFPACKET — Ignore that the UTxRxChain says that the packet has been received Continue running if more time to run
    0=Do not ignore the end of packet; 1=Ignore the end of packet
  [4] SWITCHBACKTOREF — Insert reference antenna(SWITCHPATTERN[1]) between antenna switches, from SWITCHPATTERN[2] onwards
    0=Disable (Do not insert reference antenna between switches); 1=Enable (Insert reference antenna between switches)
  [3] IGNOREMAXSPEC — Ignore the maximum number of samples and antenna slots specified with MAXTOTALSAMPLES and MAXTOTALSLOTS
    0=DoNotIgnore (Use the max specs); 1=Ignore the max specs
  [2] IGNORE8USLENGTH — Ignore the length specification in numberOf8us
    0=DoNotIgnore (Use the length specification); 1=Ignore the length specification
  [1:0] SAMPLESTARTRELATIVETO — Start point of TSAMPLEOFFSET sampling relative to which part in the switching state machine
    0=Reference (At the start of the reference antenna period); 1=Switching (At the start of antenna switching after the reference antenna period); 2=Trigger (When it is triggered Either TASKS_DFESTART, address match or AoA/AoD procedure trigger source); 3=Guard (At the start of the GUARD period)
0xD20 DFECTRL5 reset 0x10000 — Various hacker/tuning configuration for Direction finding
  [28:24] DFEOFFSETSTDHYP — Tuning of the timing difference between the hypermode demodulator and the standard demodulator for the DFE start event, in 62.5 ns units
  [18] NEVERIGNORESAT — Selects whether saturation (being reported from the radio front-end) should be ignored in the beginning of the slot or not
    0=IGNORE (Saturation being indicated from the front-end is ignored if it happens in the first 40 percent of the sample spacing after a sample was saved to RAM); 1=NEVERIGNORE (Saturation is always reported in RAM if detected by the frontend)
  [17:16] SATURATIONMODE — Set how input saturation will be present in the captured samples
    0=OFF (No saturation is presented); 1=SETMINVAL (Saturation is marked by setting both I and Q to -32768 (or mag/phase if SAMPLETYPE is 1)); 2=SATURATIONBIT (Bit 15 of both the I and Q values indicates saturation. I and Q are hence only 15 bit values)
0xD28 SWITCHPATTERN — GPIO patterns to be used for each antenna
  [7:0] SWITCHPATTERN — Fill array of GPIO patterns for antenna control
0xD2C CLEARPATTERN wo — Clear the GPIO pattern array for antenna control
  [0] CLEARPATTERN — Clear the GPIO pattern array for antenna control Behaves as a task register, but does not have PPI nor IRQ
0xD30 PSEL group — Unspecified
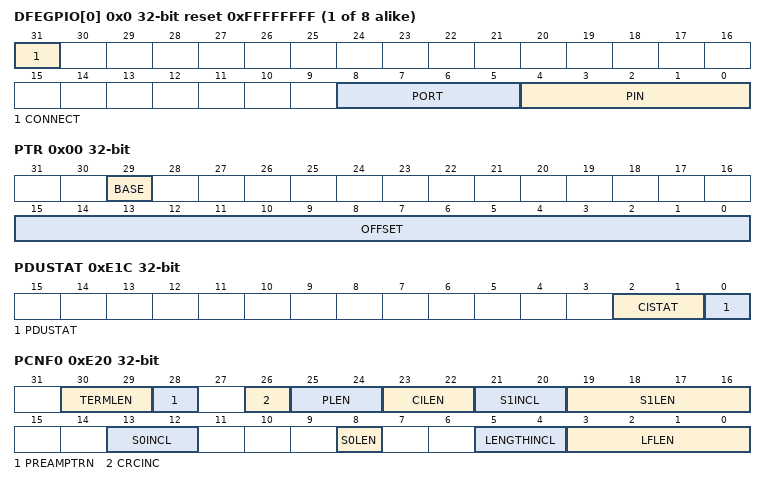
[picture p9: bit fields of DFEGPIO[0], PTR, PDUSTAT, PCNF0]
  {0x0+4j} DFEGPIO[{j}] (j=0..7) reset 0xFFFFFFFF — Description collection: Pin select for DFE pin n
    [31] CONNECT — Connection
      1=Disconnected; 0=Connected
    [8:5] PORT — Port number
    [4:0] PIN — Pin number
0xD50 DFEPACKET group — DFE packet EasyDMA channel
  0x00 PTR — Data pointer
    [29] BASE
    [15:0] OFFSET — Data pointer
  0x04 MAXCNT reset 0x1000 — Maximum number of buffer words to transfer
    [13:0] MAXCNT
  0x08 AMOUNT ro — Number of samples transferred in the last transaction
    [13:0] AMOUNT
  0x0C ENABLE — Unspecified
    [0] ENABLE
      1=Disabled; 0=Enabled
0xD64 DFEDMASTART — Manually start DmaChannelPeripheral for DFE
  [0] DFEDMASTART
0xD68 DFEDMASTOP — Force stop DmaChannelPeripheral for DFE
  [0] DFEDMASTOP
0xE00 CNTPSTART wo — Start packet counter
  [0] TRIG
0xE04 CNTPSTOP wo — Stop packet counter
  [0] TRIG
0xE08 CNTPCLEAR wo — Clear packet counter
  [0] TRIG
0xE0C CRCSTATUS ro
  [0] CRCSTATUS — CRC status of packet received
    0=CRCError (Packet received with CRC error); 1=CRCOk (Packet received with CRC ok)
0xE10 RXMATCH ro — Received address
  [2:0] RXMATCH
0xE14 RXCRC ro — CRC field of previously received packet
  [23:0] RXCRC
0xE18 DAI ro — Device address match index
  [2:0] DAI
0xE1C PDUSTAT ro — Payload status
  [2:1] CISTAT — Status on what rate packet is received with in Long Range
    0=LR125kbit (Frame is received at 125 kbps); 1=LR500kbit (Frame is received at 500 kbps)
  [0] PDUSTAT — Status on payload length vs. PCNF1.MAXLEN
    0=LessThan (Payload less than PCNF1.MAXLEN); 1=GreaterThan (Payload greater than PCNF1.MAXLEN)
0xE20 PCNF0 — Packet configuration register 0
  [30:29] TERMLEN — Length of TERM field in Long Range operation
  [28] PREAMPTRN — Preamble pattern
  [26] CRCINC — Indicates if LENGTH field contains CRC or not
    0=Exclude (LENGTH does not contain CRC); 1=Include (LENGTH includes CRC)
  [25:24] PLEN — Length of preamble on air. Decision point: TASKS_START task
    0=8-bit preamble; 1=16-bit preamble; 2=32-bit zero preamble - used for IEEE 802.15.4; 3=LongRange (Preamble - used for BLE long range)
  [23:22] CILEN — Length of code indicator - long range
  [21:20] S1INCL — Include or exclude S1 field in RAM
    0=Automatic (Include S1 field in RAM only if S1LEN > 0); 1=Include (Always include S1 field in RAM independent of S1LEN)
  [19:16] S1LEN — Length on air of S1 field in number of bits.
  [13:12] S0INCL — Include or exclude S0 field in RAM
    0=Automatic (Include S0 field only if S0LEN > 0)
  [8] S0LEN — Length on air of S0 field in number of bytes.
  [5:4] LENGTHINCL — Include or exclude LENGTH field in RAM
    0=Automatic (Include LENGTH field in RAM only if LFLEN > 0)
  [3:0] LFLEN — Length on air of LENGTH field in number of bits.
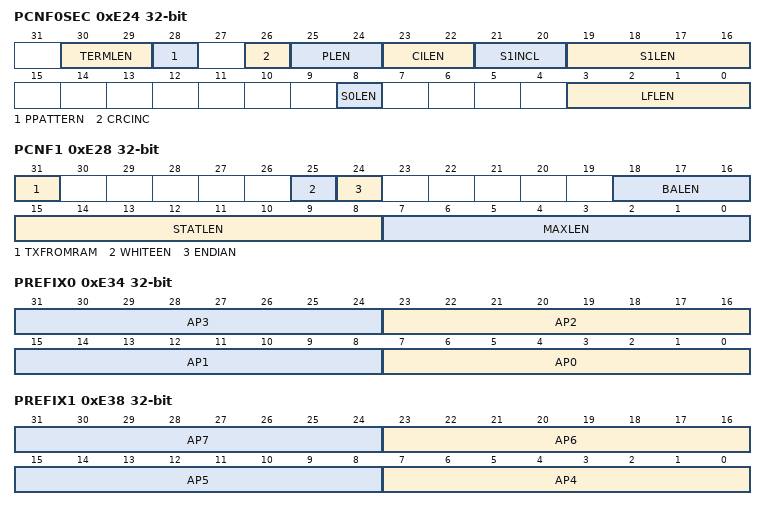
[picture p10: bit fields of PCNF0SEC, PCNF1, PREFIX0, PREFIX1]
0xE24 PCNF0SEC — Packet configuration register 0 in concurrent receive mode in BLE LR
  [30:29] TERMLEN — Length of TERM field in Long Range operation
  [28] PPATTERN
  [26] CRCINC — Indicates if LENGTH field contains CRC or not
    values as PCNF0.CRCINC
  [25:24] PLEN — Length of preamble on air. Decision point: TASKS_START task
    values as PCNF0.PLEN
  [23:22] CILEN — Length of code indicator - long range
  [21:20] S1INCL — Include or exclude S1 field in RAM
    values as PCNF0.S1INCL
  [19:16] S1LEN — Length on air of S1 field in number of bits.
  [8] S0LEN — Length on air of S0 field in number of bytes.
  [3:0] LFLEN — Length on air of LENGTH field in number of bits.
0xE28 PCNF1 — Packet configuration register 1
  [31] TXFROMRAM — Used to bypass PREAMBLE, ADDRESS, S0, LENGTH, S1 field and go straight to PAYLOAD state
    0=Disabled; 1=Bypass
  [25] WHITEEN — Enable or disable packet whitening
    0=Disabled; 1=Enabled
  [24] ENDIAN — On-air endianness of packet, this applies to the S0, LENGTH, S1, and the PAYLOAD fields.
    0=Little (Least significant bit on air first); 1=Big (Most significant bit on air first)
  [18:16] BALEN — Base address length in number of bytes
  [15:8] STATLEN — Static length in number of bytes
  [7:0] MAXLEN — Maximum length of packet payload. If the packet payload is larger than MAXLEN, the radio will truncate the payload to MAXLEN.
0xE2C BASE0 — Base address 0
0xE30 BASE1 — Base address 1
0xE34 PREFIX0 — Prefixes bytes for logical addresses 0-3
  [8n+7:8n] AP{n} (n=0..3) — Address prefix {n}
0xE38 PREFIX1 — Prefixes bytes for logical addresses 4-7
  [8n-25:8n-32] AP{n} (n=4..7) — Address prefix {n}
0xE3C TXADDRESS — Transmit address select
  [2:0] TXADDRESS
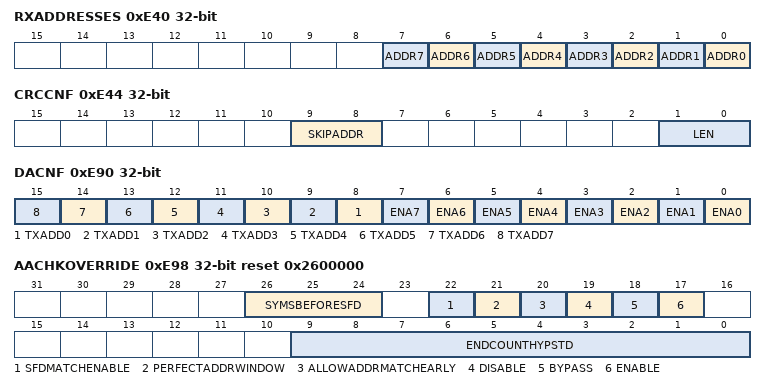
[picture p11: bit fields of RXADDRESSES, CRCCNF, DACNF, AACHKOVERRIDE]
0xE40 RXADDRESSES — Receive address select
  [all] fields
    0=Disabled; 1=Enabled
  [n] ADDR{n} (n=0..7) — Enable or disable reception on logical address {n}
0xE44 CRCCNF — CRC configuration
  [9:8] SKIPADDR — Include or exclude packet address field out of CRC calculation.
    0=Include (CRC calculation includes address field); 1=Skip (CRC calculation does not include address field. The CRC calculation will start at the first byte after the address.); 2=Ieee802154 (CRC calculation as per 802.15.4 standard. Starting at first byte after length field.)
  [1:0] LEN — CRC length in number of bytes.
    0=Disabled (CRC length is zero and CRC calculation is disabled); 1=One (CRC length is one byte and CRC calculation is enabled); 2=Two (CRC length is two bytes and CRC calculation is enabled); 3=Three (CRC length is three bytes and CRC calculation is enabled)
0xE48 CRCPOLY — CRC polynomial
  [23:0] CRCPOLY
0xE4C CRCINIT — CRC initial value
  [23:0] CRCINIT
{0xE50+4i} DAB[{i}] (i=0..7) — Description collection: Device address base segment n
  [31:0] DAB — Device address base segment n
{0xE70+4i} DAP[{i}] (i=0..7) — Description collection: Device address prefix n
  [15:0] DAP — Device address prefix n
0xE90 DACNF — Device address match configuration
  [n+8] TXADD{n} (n=0..7) — TxAdd for device address {n}
  [n] ENA{n} (n=0..7) — Enable or disable device address matching using device address {n}
    0=Disabled; 1=Enabled
0xE94 BCC — Bit counter compare
0xE98 AACHKOVERRIDE reset 0x2600000 — Address Check Override
  [26:24] SYMSBEFORESFD — Number of preamble symbols before SFD to match, by default 2 symbols.
  [22] SFDMATCHENABLE — Enable every 4 bits SFD match for IEEE 802.15.4
    0=Disable; 1=Enable
  [21] PERFECTADDRWINDOW — Enable timing accurate address match window in demodulator
    0=DISABLE (The address window has some margin); 1=ENABLE (The address window spans only one bit)
  [20] ALLOWADDRMATCHEARLY — Enable ignore std AA checker before shift register filled
    0=ENABLE; 1=DISABLE
  [19] DISABLE — Disable std AA checker
    0=ENABLE (Enable std AA checker); 1=DISABLE (Disable std AA checker)
  [18] BYPASS — Bypass majority vote
    0=PASS (Majority vote); 1=BYPASS (Bypass through majority vote)
  [17] ENABLE — Enable AA bit 15 check
    0=AA16to31 (Enable AA16..31); 1=AA15to31 (Enable AA15..31)
  [9:0] ENDCOUNTHYPSTD — Defines maximum number of PDU bits to compare between Hyper and Std demodulator
0xE9C PACKETCNTR1 ro — Unspecified
  [15:0] COUNTER — Packet counter value
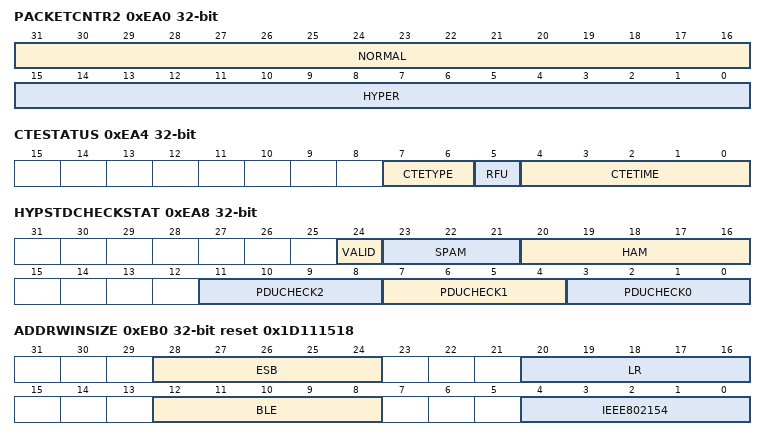
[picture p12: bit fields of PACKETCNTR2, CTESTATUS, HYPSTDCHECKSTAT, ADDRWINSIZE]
0xEA0 PACKETCNTR2 ro — Unspecified
  [31:16] NORMAL — Packet counter value (number of packets with addressmatch ok)
  [15:0] HYPER — Number of detected correlator syncs
0xEA4 CTESTATUS ro — CTEInfo parsed from received packet
  [7:6] CTETYPE — CTEType parsed from packet
  [5] RFU — RFU parsed from packet
  [4:0] CTETIME — CTETime parsed from packet
0xEA8 HYPSTDCHECKSTAT ro — Address Check Override
  [24] VALID — Valid flag bit
  [23:21] SPAM — Time distance #bit clock cycles from AAmatchHyp.
  [20:16] HAM — Hamming distance between std demod AA15:0 and expected AA15:0.
  [11:8] PDUCHECK2 — Number of bits where Std and Hyper demodulator disagrees for maximum latency.
  [7:4] PDUCHECK1 — Number of bits where Std and Hyper demodulator disagrees for medium latency.
  [3:0] PDUCHECK0 — Number of bits where Std and Hyper demodulator disagrees for minimum latency.
0xEAC HYPSTDAADIFFVEC ro — Address Diff Vector
  [15:0] DIFF — Hyper AA15:0 and Std AA15:0 differs
0xEB0 ADDRWINSIZE reset 0x1D111518 — Address match safe window size (the number of bits after detect is asserted, before starting to look for address match). Only valid when OVERRIDE22.DISABLEADDRWINDOW is '0'.
  [28:24] ESB — Number of bits after detect to start search address/SFD in ESB mode
  [20:16] LR — Number of bits after detect to start search address/SFD in BLE_LR_125k/BLE_LR_500k mode
  [12:8] BLE — Number of bits after detect to start search address/SFD in BLE mode
  [4:0] IEEE802154 — Number of bits after detect to start search address/SFD in IEEE 802.15.4 mode
0xEB4 MHRMATCHCONF — Search pattern configuration
0xEB8 MHRMATCHMASK — Pattern mask
0xEBC SFD reset 0xA7 — IEEE 802.15.4 start of frame delimiter
  [7:0] SFD
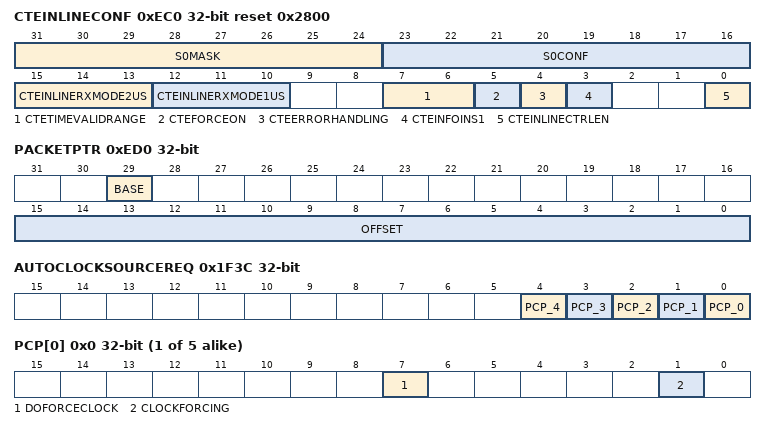
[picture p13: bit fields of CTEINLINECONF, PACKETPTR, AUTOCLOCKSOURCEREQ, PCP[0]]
0xEC0 CTEINLINECONF reset 0x2800 — Configuration for CTE inline mode
  [31:24] S0MASK — S0 bit mask to set which bit to match
  [23:16] S0CONF — S0 bit pattern to match
  [15:13] CTEINLINERXMODE2US — Spacing between samples for the samples in the SWITCHING period when CTEINLINEMODE is set
    values as DFECTRL1.TSAMPLESPACINGREF
  [12:10] CTEINLINERXMODE1US — Spacing between samples for the samples in the SWITCHING period when CTEINLINEMODE is set
    values as DFECTRL1.TSAMPLESPACINGREF
  [7:6] CTETIMEVALIDRANGE — Max range of CTETime
    0=20 in 8us unit (default) Set to 20 if parsed CTETime is larger han 20; 1=31 in 8us unit; 2=63 in 8us unit
  [5] CTEFORCEON — CTE is continuously output after CRC and only stopped by triggering TASKS_STOP. This is typically used together with the DFEEND to STOP short. AoA/AoD procedure duration is still controlled by DFECTRL1.NUMBEROF8S / CTETIME
    1=Yes (CTE is continuously transmitted after CRC until TASKS_STOP); 0=No (CTE duration is automatically determined by DFECTRL1.NUMBEROF8US / CTETIME (only correct for 1Mbps and 2Mbps modes))
  [4] CTEERRORHANDLING — Sampling/switching if CRC is not OK
    1=Yes (Sampling and antenna switching also when CRC is not OK); 0=No (No sampling and antenna switching when CRC is not OK)
  [3] CTEINFOINS1 — CTEInfo is S1 byte or not
    1=InS1 (CTEInfo is in S1 byte (data PDU)); 0=NotInS1 (CTEInfo is NOT in S1 byte (advertising PDU))
  [0] CTEINLINECTRLEN — Enable parsing of CTEInfo from received packet in BLE modes
    1=Enabled (Parsing of CTEInfo is enabled); 0=Disabled (Parsing of CTEInfo is disabled)
0xEC4 DMASTART wo — Unspecified
  [0] TRIG
0xEC8 DMASTOP wo — Unspecified
  [0] TRIG
0xECC DMAENABLE — Unspecified
  [0] ENABLE
0xED0 PACKETPTR — Unspecified
  [29] BASE, [15:0] OFFSET
0xED4 DMAAMOUNT ro — Unspecified
  [8:0] AMOUNT
0xED8 DMAMAXCNT reset 0x103 — Unspecified
  [8:0] MAXCNT
0x1F00 PENALTYTRIGPCP4 group — Unspecified
  0x00 ZERO wo — Unspecified
    [0] TRIG
  0x04 FULL wo — Unspecified
    [0] TRIG
0x1F08 PENALTYTRIGPCP3 group — Unspecified
  0x00 ZERO wo — Unspecified
    [0] TRIG
  0x04 FULL wo — Unspecified
    [0] TRIG
0x1F10 PENALTYTRIGPCP2 group — Unspecified
  0x00 ZERO wo — Unspecified
    [0] TRIG
  0x04 FULL wo — Unspecified
    [0] TRIG
0x1F18 PENALTYTRIGPCP1 group — Unspecified
  0x00 ZERO wo — Unspecified
    [0] TRIG
  0x04 FULL wo — Unspecified
    [0] TRIG
0x1F20 PENALTYTRIGPCP0 group — Unspecified
  0x00 ZERO wo — Unspecified
    [0] TRIG
  0x04 FULL wo — Unspecified
    [0] TRIG
0x1F28 PENALTYREG group — Unspecified
  0x00 PCP0 wo — Unspecified
    [31:0] VALUE
  {0x0+4j} PCP[{j}] (j=0..3) wo reset 0xFFFFFFFC (alternate view of PCP0) — Description collection:
    [31:0] VALUE
0x1F3C AUTOCLOCKSOURCEREQ ro — Unspecified
  [all] fields
    0=On (Unspecified); 1=Off (Unspecified)
  [n] PCP_{n} (n=0..4)
0x1F40 FORCEOVERRIDE group — Unspecified
  {0x0+4j} PCP[{j}] (j=0..4) — Description collection:
    [7] DOFORCECLOCK, [1] CLOCKFORCING
